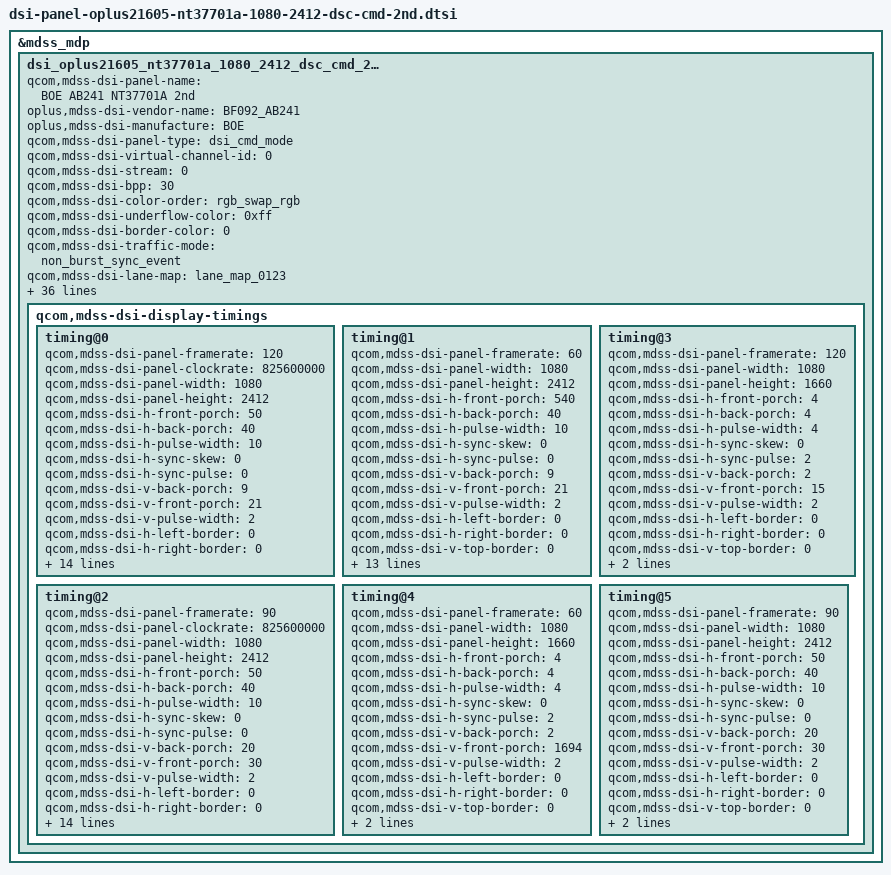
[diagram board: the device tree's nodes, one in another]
&mdss_mdp {
	dsi_oplus21605_nt37701a_1080_2412_dsc_cmd_2nd: qcom,mdss_dsi_oplus21605_nt37701a_1080_2412_dsc_cmd_2nd {
		qcom,mdss-dsi-panel-name = "BOE AB241 NT37701A 2nd";
		oplus,mdss-dsi-vendor-name = "BF092_AB241";
		oplus,mdss-dsi-manufacture = "BOE";
		qcom,mdss-dsi-panel-type = "dsi_cmd_mode";
		qcom,mdss-dsi-virtual-channel-id = <0>;
		qcom,mdss-dsi-stream = <0>;
		qcom,mdss-dsi-bpp = <30>;
		qcom,mdss-dsi-color-order = "rgb_swap_rgb";
		qcom,mdss-dsi-underflow-color = <0xff>;
		qcom,mdss-dsi-border-color = <0>;
		//qcom,dsi-ctrl-num = <0>;
		//qcom,dsi-phy-num = <0>;
		qcom,mdss-dsi-traffic-mode = "non_burst_sync_event";
		qcom,mdss-dsi-lane-map = "lane_map_0123";
		qcom,mdss-dsi-bllp-eof-power-mode;
		qcom,mdss-dsi-bllp-power-mode;
		qcom,mdss-dsi-lane-0-state;
		qcom,mdss-dsi-lane-1-state;
		qcom,mdss-dsi-lane-2-state;
		qcom,mdss-dsi-lane-3-state;
		qcom,mdss-dsi-dma-trigger = "trigger_sw";
		qcom,mdss-dsi-mdp-trigger = "none";
		qcom,mdss-dsi-reset-sequence = <1 10>, <0 10>, <1 10>;

		qcom,mdss-dsi-te-pin-select = <1>;
		qcom,mdss-dsi-te-dcs-command = <1>;
		qcom,mdss-dsi-te-check-enable;
		qcom,mdss-dsi-te-using-te-pin;
		qcom,mdss-dsi-lp11-init;
		qcom,mdss-dsi-wr-mem-start = <0x2c>;
		qcom,mdss-dsi-wr-mem-continue = <0x3c>;
		qcom,mdss-dsi-panel-hdr-enabled;
		qcom,mdss-dsi-panel-hdr-color-primaries = <15635 16450 34000 16000 13250 34500 7500 3000>;
		qcom,mdss-dsi-panel-peak-brightness = <5400000>;
		qcom,mdss-dsi-panel-blackness-level = <2000>;
		qcom,mdss-pan-physical-width-dimension = <70>;
		qcom,mdss-pan-physical-height-dimension = <153>;
		//qcom,esd-check-enabled;
		qcom,mdss-dsi-panel-status-check-mode = "reg_read";
		qcom,mdss-dsi-panel-status-command = [06 01 00 01 05 00 02 0A 00
							06 01 00 01 05 00 02 05 00
							06 01 00 01 05 00 02 03 00
							06 01 00 01 05 00 02 0e 00];
		qcom,mdss-dsi-panel-status-command-state = "dsi_hs_mode";
		qcom,mdss-dsi-panel-status-value = <0x9f 0x00 0x01 0x80>;
		qcom,mdss-dsi-panel-status-read-length = <1 1 1 1>;
		//oplus,esd-err-flag-check-enabled;
		//oplus,esd-err-flag-gpio = <&tlmm 84 0>;
		//oplus,esd-err-trigger-polarity = <1>;
		qcom,dynamic-mode-switch-enabled;
		qcom,dynamic-mode-switch-type = "dynamic-resolution-switch-immediate";
		qcom,mdss-dsi-display-timings {
			timing@0 {
				qcom,mdss-dsi-panel-framerate = <120>;
				qcom,mdss-dsi-panel-clockrate = <825600000>;
				qcom,mdss-dsi-panel-width = <1080>;
				qcom,mdss-dsi-panel-height = <2412>;
				qcom,mdss-dsi-h-front-porch = <50>;
				qcom,mdss-dsi-h-back-porch = <40>;
				qcom,mdss-dsi-h-pulse-width = <10>;
				qcom,mdss-dsi-h-sync-skew = <0>;
				qcom,mdss-dsi-h-sync-pulse = <0>;
				qcom,mdss-dsi-v-back-porch = <9>;
				qcom,mdss-dsi-v-front-porch = <21>;
				qcom,mdss-dsi-v-pulse-width = <2>;
				qcom,mdss-dsi-h-left-border = <0>;
				qcom,mdss-dsi-h-right-border = <0>;
				qcom,mdss-dsi-v-top-border = <0>;
				qcom,mdss-dsi-v-bottom-border = <0>;
				qcom,mdss-dsi-panel-jitter = <0x4 0x1>;
				oplus,fod-on-vblank = <0>;
				oplus,fod-off-vblank = <3>;
				qcom,compression-mode = "dsc";
				qcom,mdss-dsc-slice-height = <12>;
				qcom,mdss-dsc-slice-width = <540>;
				qcom,mdss-dsc-slice-per-pkt = <2>;
				qcom,mdss-dsc-bit-per-component = <10>;
				qcom,mdss-dsc-bit-per-pixel = <8>;
				qcom,mdss-dsc-block-prediction-enable;
				qcom,mdss-dsc-version = <0x11>;
				qcom,mdss-dsc-scr-version = <1>;
			};
			timing@1 {
				qcom,mdss-dsi-panel-framerate = <60>;
				//qcom,mdss-dsi-panel-clockrate = <960000000>;
				qcom,mdss-dsi-panel-width = <1080>;
				qcom,mdss-dsi-panel-height = <2412>;
				qcom,mdss-dsi-h-front-porch = <540>;
				qcom,mdss-dsi-h-back-porch = <40>;
				qcom,mdss-dsi-h-pulse-width = <10>;
				qcom,mdss-dsi-h-sync-skew = <0>;
				qcom,mdss-dsi-h-sync-pulse = <0>;
				qcom,mdss-dsi-v-back-porch = <9>;
				qcom,mdss-dsi-v-front-porch = <21>;
				qcom,mdss-dsi-v-pulse-width = <2>;
				qcom,mdss-dsi-h-left-border = <0>;
				qcom,mdss-dsi-h-right-border = <0>;
				qcom,mdss-dsi-v-top-border = <0>;
				qcom,mdss-dsi-v-bottom-border = <0>;
				qcom,mdss-dsi-panel-jitter = <0x4 0x1>;
				oplus,fod-on-vblank = <0>;
				oplus,fod-off-vblank = <3>;
				qcom,compression-mode = "dsc";
				qcom,mdss-dsc-slice-height = <12>;
				qcom,mdss-dsc-slice-width = <540>;
				qcom,mdss-dsc-slice-per-pkt = <2>;
				qcom,mdss-dsc-bit-per-component = <10>;
				qcom,mdss-dsc-bit-per-pixel = <8>;
				qcom,mdss-dsc-block-prediction-enable;
				qcom,mdss-dsc-version = <0x11>;
				qcom,mdss-dsc-scr-version = <1>;
			};
			timing@2 {
				qcom,mdss-dsi-panel-framerate = <90>;
				qcom,mdss-dsi-panel-clockrate = <825600000>;
				qcom,mdss-dsi-panel-width = <1080>;
				qcom,mdss-dsi-panel-height = <2412>;
				qcom,mdss-dsi-h-front-porch = <50>;
				qcom,mdss-dsi-h-back-porch = <40>;
				qcom,mdss-dsi-h-pulse-width = <10>;
				qcom,mdss-dsi-h-sync-skew = <0>;
				qcom,mdss-dsi-h-sync-pulse = <0>;
				qcom,mdss-dsi-v-back-porch = <20>;
				qcom,mdss-dsi-v-front-porch = <30>;
				qcom,mdss-dsi-v-pulse-width = <2>;
				qcom,mdss-dsi-h-left-border = <0>;
				qcom,mdss-dsi-h-right-border = <0>;
				qcom,mdss-dsi-v-top-border = <0>;
				qcom,mdss-dsi-v-bottom-border = <0>;
				qcom,mdss-dsi-panel-jitter = <0x4 0x1>;
				oplus,fod-on-vblank = <0>;
				oplus,fod-off-vblank = <3>;
				qcom,compression-mode = "dsc";
				qcom,mdss-dsc-slice-height = <12>;
				qcom,mdss-dsc-slice-width = <540>;
				qcom,mdss-dsc-slice-per-pkt = <2>;
				qcom,mdss-dsc-bit-per-component = <10>;
				qcom,mdss-dsc-bit-per-pixel = <8>;
				qcom,mdss-dsc-block-prediction-enable;
				qcom,mdss-dsc-version = <0x11>;
				qcom,mdss-dsc-scr-version = <1>;
			};
			timing@3 {
				qcom,mdss-dsi-panel-framerate = <120>;
				//qcom,mdss-dsi-panel-clockrate = <1320000000>;
				qcom,mdss-dsi-panel-width = <1080>;
				qcom,mdss-dsi-panel-height = <1660>;
				qcom,mdss-dsi-h-front-porch = <4>;
				qcom,mdss-dsi-h-back-porch = <4>;
				qcom,mdss-dsi-h-pulse-width = <4>;
				qcom,mdss-dsi-h-sync-skew = <0>;
				qcom,mdss-dsi-h-sync-pulse = <2>;
				qcom,mdss-dsi-v-back-porch = <2>;
				qcom,mdss-dsi-v-front-porch = <15>;
				qcom,mdss-dsi-v-pulse-width = <2>;
				qcom,mdss-dsi-h-left-border = <0>;
				qcom,mdss-dsi-h-right-border = <0>;
				qcom,mdss-dsi-v-top-border = <0>;
				qcom,mdss-dsi-v-bottom-border = <0>;
				qcom,mdss-dsi-panel-jitter = <0x4 0x1>;
			};
			timing@4 {
				qcom,mdss-dsi-panel-framerate = <60>;
				//qcom,mdss-dsi-panel-clockrate = <1320000000>;
				qcom,mdss-dsi-panel-width = <1080>;
				qcom,mdss-dsi-panel-height = <1660>;
				qcom,mdss-dsi-h-front-porch = <4>;
				qcom,mdss-dsi-h-back-porch = <4>;
				qcom,mdss-dsi-h-pulse-width = <4>;
				qcom,mdss-dsi-h-sync-skew = <0>;
				qcom,mdss-dsi-h-sync-pulse = <2>;
				qcom,mdss-dsi-v-back-porch = <2>;
				qcom,mdss-dsi-v-front-porch = <1694>;
				qcom,mdss-dsi-v-pulse-width = <2>;
				qcom,mdss-dsi-h-left-border = <0>;
				qcom,mdss-dsi-h-right-border = <0>;
				qcom,mdss-dsi-v-top-border = <0>;
				qcom,mdss-dsi-v-bottom-border = <0>;
				qcom,mdss-dsi-panel-jitter = <0x4 0x1>;
			};
			timing@5 {
				qcom,mdss-dsi-panel-framerate = <90>;
				//qcom,mdss-dsi-panel-clockrate = <1320000000>;
				qcom,mdss-dsi-panel-width = <1080>;
				qcom,mdss-dsi-panel-height = <2412>;
				qcom,mdss-dsi-h-front-porch = <50>;
				qcom,mdss-dsi-h-back-porch = <40>;
				qcom,mdss-dsi-h-pulse-width = <10>;
				qcom,mdss-dsi-h-sync-skew = <0>;
				qcom,mdss-dsi-h-sync-pulse = <0>;
				qcom,mdss-dsi-v-back-porch = <20>;
				qcom,mdss-dsi-v-front-porch = <30>;
				qcom,mdss-dsi-v-pulse-width = <2>;
				qcom,mdss-dsi-h-left-border = <0>;
				qcom,mdss-dsi-h-right-border = <0>;
				qcom,mdss-dsi-v-top-border = <0>;
				qcom,mdss-dsi-v-bottom-border = <0>;
				qcom,mdss-dsi-panel-jitter = <0x4 0x1>;
			};
		};
	};
};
